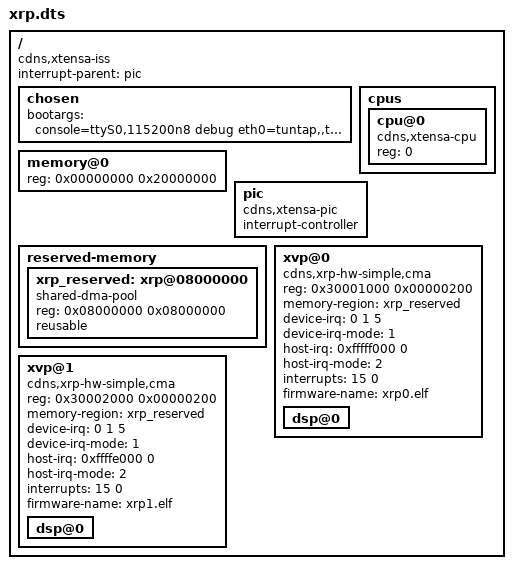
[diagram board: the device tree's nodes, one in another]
/dts-v1/;

/ {
	compatible = "cdns,xtensa-iss";
	#address-cells = <1>;
	#size-cells = <1>;
	interrupt-parent = <&pic>;

	chosen {
		bootargs = "console=ttyS0,115200n8 debug eth0=tuntap,,tap9 root=/dev/simdisk0";
	};

	memory@0 {
		device_type = "memory";
		reg = <0x00000000 0x20000000>;
	};

	cpus {
		#address-cells = <1>;
		#size-cells = <0>;
		cpu@0 {
			compatible = "cdns,xtensa-cpu";
			reg = <0>;
		};
	};

	pic: pic {
		compatible = "cdns,xtensa-pic";
		/* one cell: internal irq number,
		 * two cells: second cell == 0: internal irq number
		 *            second cell == 1: external irq number
		 */
		#interrupt-cells = <2>;
		interrupt-controller;
	};

	reserved-memory {
		#address-cells = <1>;
		#size-cells = <1>;
		ranges;

		xrp_reserved: xrp@08000000 {
			compatible = "shared-dma-pool";
			reg = <0x08000000 0x08000000>;
			reusable;
		};
	};

	xvp@0 {
		#address-cells = <1>;
		#size-cells = <1>;
		compatible = "cdns,xrp-hw-simple,cma";
		reg = <0x30001000 0x00000200>;
		memory-region = <&xrp_reserved>;
		device-irq = <0 1 5>; /* offset, bit#, IRQ# */
		device-irq-mode = <1>;
		host-irq = <0xfffff000 0>; /* offset, bit# */
		host-irq-mode = <2>;
		interrupts = <15 0>;
		firmware-name = "xrp0.elf";
		ranges = <0x00000000 0x00000000 0x20000000
			        0xcff80000 0x20000000 0x00040000
			        0xcffc0000 0x20040000 0x00040000
			        0xd0000000 0x20080000 0x00008000
			        0xd0080000 0xd0080000 0x01000000
			        0xe0000000 0xe0000000 0x20000000>;
		dsp@0 {
		};
	};

	xvp@1 {
		#address-cells = <1>;
		#size-cells = <1>;
		compatible = "cdns,xrp-hw-simple,cma";
		reg = <0x30002000 0x00000200>;
		memory-region = <&xrp_reserved>;
		device-irq = <0 1 5>; /* offset, bit#, IRQ# */
		device-irq-mode = <1>;
		host-irq = <0xffffe000 0>; /* offset, bit# */
		host-irq-mode = <2>;
		interrupts = <15 0>;
		firmware-name = "xrp1.elf";
		ranges = <0x00000000 0x00000000 0x20000000
			        0xcff80000 0x200c0000 0x00040000
			        0xcffc0000 0x20100000 0x00040000
			        0xd0000000 0x20140000 0x00008000
			        0xd0080000 0xd0080000 0x01000000
			        0xe0000000 0xe0000000 0x20000000>;
		dsp@0 {
		};
	};

};
